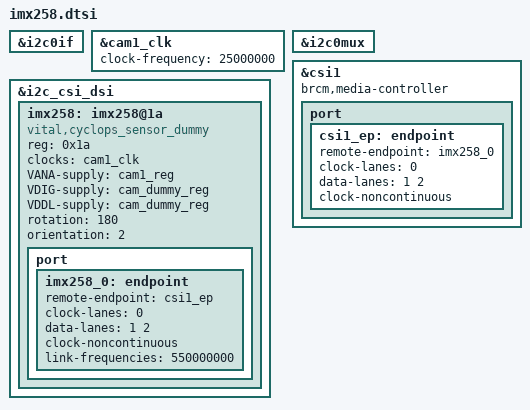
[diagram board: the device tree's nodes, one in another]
#include <dt-bindings/gpio/gpio.h>

&i2c0if {
  status = "okay";
};

&cam1_clk {
  status = "okay";
  clock-frequency = <25000000>;
};

&i2c0mux {
  status = "okay";
};

&i2c_csi_dsi {
  #address-cells = <1>;
  #size-cells = <0>;
  status = "okay";

  imx258: imx258@1a {
    compatible = "vital,cyclops_sensor_dummy";
    reg = <0x1a>;
    status = "okay";

    clocks = <&cam1_clk>;
    clock-names = "xclk";

    VANA-supply = <&cam1_reg>;  /* 2.8v */
    VDIG-supply = <&cam_dummy_reg>;  /* 1.8v */
    VDDL-supply = <&cam_dummy_reg>;  /* 1.2v */

    rotation = <180>;
    orientation = <2>;

    port {
      imx258_0: endpoint {
        remote-endpoint = <&csi1_ep>;
        clock-lanes = <0>;
        data-lanes = <1 2>;
        clock-noncontinuous;
        link-frequencies = /bits/ 64 <550000000>;
      };
    };
  };
};

&csi1 {
  status = "okay";
  brcm,media-controller;

  port {
    csi1_ep: endpoint {
      remote-endpoint = <&imx258_0>;
      clock-lanes = <0>;
      data-lanes = <1 2>;
      clock-noncontinuous;
    };
  };
};
